# INSTR_PRM register map
Vendor: Texas Instruments
Peripheral module from a debugger description file (folder omap4430).
Registers are 32-bit, access per field, reset 0x0 unless marked. A register's access mark holds for its fields unless they carry their own. Offsets are as the file gives them; lines under a group give offsets from that group; [hi:lo] are bit positions; {n}, {i} and the like mark numbered series; 'fields as' and 'values as' point back to an identical list; <NAME> marks a mode.

## INSTR_PRM
0x00 PMI_IDENTICATION ro reset not defined — PM profiling identification register
  [31:0] REVISION — IP revision
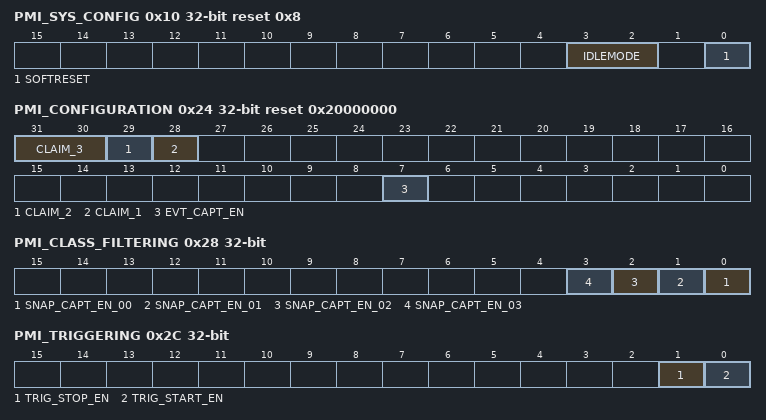
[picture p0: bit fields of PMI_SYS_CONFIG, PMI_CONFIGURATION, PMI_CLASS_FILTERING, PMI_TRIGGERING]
0x10 PMI_SYS_CONFIG reset 0x8 — PM profiling system configuartion register
  [3:2] IDLEMODE rw — Configuration of the local tartget state management mode
  [0] SOFTRESET rw — Software reset
0x14 PMI_STATUS ro reset 0x100 — PM profiling status register
  [8] FIFOEMPTY — PM Profiling buffer empty
0x24 PMI_CONFIGURATION reset 0x20000000 — PM profiling configuration register
  [31:30] CLAIM_3 rw — Ownership
  [29] CLAIM_2 rw — Debugger override qualifier
  [28] CLAIM_1 ro — Current owner
  [7] EVT_CAPT_EN rw — When HIGH the PM events capture is enabled
0x28 PMI_CLASS_FILTERING — PM profiling class filtering register
  [n] SNAP_CAPT_EN_{n:02} rw (n=0..3) — Snapshot capture enable - Class-ID = {0x0+n}
0x2C PMI_TRIGGERING — PM profiling triggering control register
  [1] TRIG_STOP_EN rw — Enable stop capturing PM events from external trigger detection
  [0] TRIG_START_EN rw — Enable start capturing PM events from external trigger detection
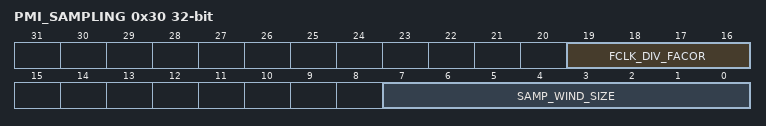
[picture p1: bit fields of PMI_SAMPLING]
0x30 PMI_SAMPLING — PM profiling sampling window register
  [19:16] FCLK_DIV_FACOR rw — FunClk divide factor ranging from 1 to 16
  [7:0] SAMP_WIND_SIZE rw — PM events sampling window size
